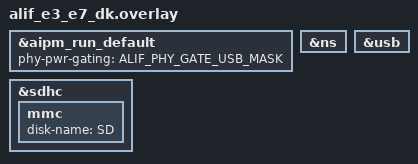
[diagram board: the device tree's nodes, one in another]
/*
 * SPDX-FileCopyrightText: Copyright Alif Semiconductor
 * SPDX-License-Identifier: Apache-2.0
 */

#include <dt-bindings/misc/alif_aipm_common.h>

&aipm_run_default {
	phy-pwr-gating = <ALIF_PHY_GATE_USB_MASK>;
};

&ns {
	status = "okay";
};

zephyr_udc0: &usb {
	status = "okay";
};

&sdhc {
	status = "okay";

	mmc {
		status = "okay";
		disk-name = "SD";
	};
};

